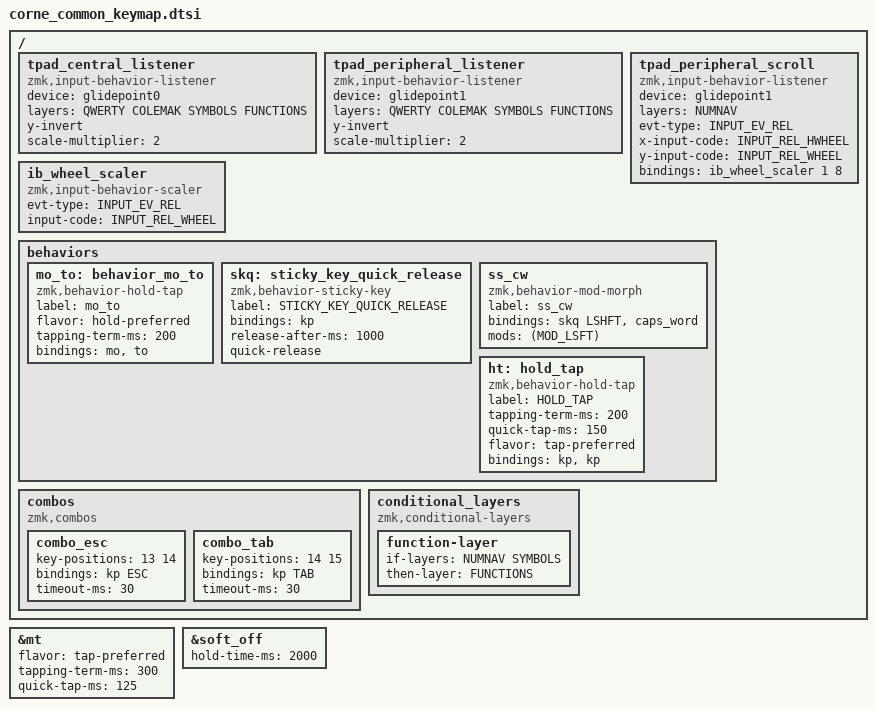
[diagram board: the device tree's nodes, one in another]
#include <behaviors.dtsi>
#include <dt-bindings/zmk/keys.h>
#include <dt-bindings/zmk/bt.h> 
#include <dt-bindings/zmk/rgb.h>
#include <dt-bindings/zmk/ext_power.h>
#include <dt-bindings/zmk/outputs.h>

#include <dt-bindings/zmk/mouse.h>
#include <behaviors/mouse_keys.dtsi>


#define QWERTY 0
#define COLEMAK 1
#define NUMNAV 2
#define SYMBOLS 3
#define FUNCTIONS 4

/ {
    /* assign `input-listener` to all pointing devices */
    /* &glidepoint0 on central, &glidepoint1 on peripheral */
    tpad_central_listener {
        compatible = "zmk,input-behavior-listener";
        device = <&glidepoint0>;
        layers = <QWERTY COLEMAK SYMBOLS FUNCTIONS>;
        y-invert;
        scale-multiplier = <2>;
    };

    tpad_peripheral_listener {
        compatible = "zmk,input-behavior-listener";
        device = <&glidepoint1>;
        layers = <QWERTY COLEMAK SYMBOLS FUNCTIONS>;
        y-invert;
        scale-multiplier = <2>;
    };

    tpad_peripheral_scroll {
        compatible = "zmk,input-behavior-listener";
        device = <&glidepoint1>;
        layers = <NUMNAV>;
        evt-type = <INPUT_EV_REL>;
        x-input-code = <INPUT_REL_HWHEEL>;
        y-input-code = <INPUT_REL_WHEEL>;
        bindings = <&ib_wheel_scaler 1 8>;
    };

    ib_wheel_scaler: ib_wheel_scaler {
        compatible = "zmk,input-behavior-scaler";
        #binding-cells = <2>;
        evt-type = <INPUT_EV_REL>;
        input-code = <INPUT_REL_WHEEL>;
    };
};

&mt {
  flavor = "tap-preferred";
  tapping-term-ms = <300>; 
  quick-tap-ms = <125>;
};

&soft_off {
    hold-time-ms = <2000>;
};

/ {
  behaviors {
    mo_to: behavior_mo_to {
         compatible = "zmk,behavior-hold-tap";
         label = "mo_to";
         #binding-cells = <2>;
         flavor = "hold-preferred";
         tapping-term-ms = <200>;
         bindings = <&mo>, <&to>;
    };

    skq: sticky_key_quick_release {
        compatible = "zmk,behavior-sticky-key";
        label = "STICKY_KEY_QUICK_RELEASE";
        #binding-cells = <1>;
        bindings = <&kp>;
        release-after-ms = <1000>;
        quick-release;
    };

    ss_cw: ss_cw {
         compatible = "zmk,behavior-mod-morph";
         #binding-cells = <0>;
         label = "ss_cw";
         bindings = <&skq LSHFT>, <&caps_word>;
         mods = <(MOD_LSFT)>;
    };

    ht: hold_tap {
        compatible = "zmk,behavior-hold-tap";
        label = "HOLD_TAP";
        #binding-cells = <2>;
        tapping-term-ms = <200>;
        quick-tap-ms = <150>;
        flavor = "tap-preferred";
        bindings = <&kp>, <&kp>;
    };
  };

  combos {
    compatible = "zmk,combos";

    combo_esc {
      key-positions = <13 14>;
      bindings = <&kp ESC>;
      timeout-ms = <30>;
    };

    combo_tab {
      key-positions = <14 15>;
      bindings = <&kp TAB>;
      timeout-ms = <30>;
    };
  };

  conditional_layers {
    compatible = "zmk,conditional-layers";
    function-layer {
      if-layers = <NUMNAV SYMBOLS>;
      then-layer = <FUNCTIONS>;
    };
  };
};

// QWERTY Layer (Corne 42 keys)
// -----------------------------------------------------------------------------------------
// | TAB  |  Q  |  W  |  E  |  R  |  T  |   |  Y  |  U   |  I  |  O  |  P  | BKSP |
// |CTRL  |  A  |  S  |  D  |  F  |  G  |   |  H  |  J   |  K  |  L  |  ;  |  '   |
// |SHFT  |  Z  |  X  |  C  |  V  |  B  |   |  N  |  M   |  ,  |  .  |  /  | ESC  |
//                    | WIN | NUM | SPC |   | ENT | SYM  | ALT  |

#define __________QWERTY_L1__________  &kp TAB    &kp Q  &kp W  &kp E        &kp R        &kp T
#define __________QWERTY_L2__________  &kp LCTRL  &kp A  &kp S  &kp D        &kp F        &kp G
#define __________QWERTY_L3__________  &kp LSHFT  &kp Z  &kp X  &kp C        &kp V        &kp B
#define _____QWERTY_TH_L_____  &kp LEFT_GUI &mo NUMNAV &kp SPACE

#define __________QWERTY_R1__________  &kp Y      &kp U      &kp I         &kp O        &kp P          &kp BACKSPACE
#define __________QWERTY_R2__________  &kp H      &kp J      &kp K         &kp L        &kp SEMICOLON  &kp SQT
#define __________QWERTY_R3__________  &kp N      &kp M      &kp COMMA     &kp PERIOD   &kp SLASH      &kp ESCAPE
#define _____QWERTY_TH_R_____  &kp ENTER &mo SYMBOLS &kp LEFT_ALT

// COLEMAK Layer
// -----------------------------------------------------------------------------------------
// | TAB  |  Q  |  W  |  F  |  P  |  G  |   |  J  |  L   |  U  |  Y  |  ;  | BKSP |
// |CTRL  |  A  |  R  |  S  |  T  |  D  |   |  H  |  N   |  E  |  I  |  O  |  '   |
// |SHFT  |  Z  |  X  |  C  |  V  |  B  |   |  K  |  M   |  ,  |  .  |  /  | ESC  |
//                    | WIN | NUM | SPC |   | ENT | SYM  | ALT  |

#define __________COLEMAK_L1__________  &kp TAB    &kp Q  &kp W  &kp F        &kp P        &kp G
#define __________COLEMAK_L2__________  &kp LCTRL  &kp A  &kp R  &kp S        &kp T        &kp D
#define __________COLEMAK_L3__________  &kp LSHFT  &kp Z  &kp X  &kp C        &kp V        &kp B
#define _____COLEMAK_TH_L_____  &kp LEFT_GUI &mo NUMNAV &kp SPACE

#define __________COLEMAK_R1__________  &kp J      &kp L      &kp U         &kp Y        &kp SEMICOLON  &kp BACKSPACE
#define __________COLEMAK_R2__________  &kp H      &kp N      &kp E         &kp I        &kp O          &kp SQT
#define __________COLEMAK_R3__________  &kp K      &kp M      &kp COMMA     &kp PERIOD   &kp SLASH      &kp ESCAPE
#define _____COLEMAK_TH_R_____  &kp ENTER &mo SYMBOLS &kp LEFT_ALT

// NUM-NAV Layer (combines number pad and navigation)
// -----------------------------------------------------------------------------------------
// | TAB  |  ---  |  7  |  8  |  9  |  ,  |   | --- | C+← |  UP | C+→ | PGUP |  BKSP |
// | CTRL | ---   |  4  |  5  |  6  |  0  |   | --- | LFT | DWN | RGT | INS  | DEL |
// | SHFT  | ---  |  1  |  2  |  3  |  .  |   | --- | HOM | C+X | END | PGDN | ---  |
//                      | --- | --- | SPC |   | RET | --- | --- |

#define __________NUMNAV_L1__________  &kp TAB     &trans  &kp N7        &kp N8        &kp N9        &kp COMMA
#define __________NUMNAV_L2__________  &kp LCTRL   &trans  &kp NUMBER_4  &kp N5        &kp NUMBER_6  &kp N0
#define __________NUMNAV_L3__________  &kp LSHFT   &trans  &kp NUMBER_1  &kp NUMBER_2  &kp NUMBER_3  &kp PERIOD
#define _____NUMNAV_TH_L_____  &trans &trans &kp SPACE

#define __________NUMNAV_R1__________  &trans  &kp LC(LEFT)    &kp UP    &kp LC(RIGHT)  &kp PAGE_UP    &kp BACKSPACE
#define __________NUMNAV_R2__________  &trans  &kp LEFT_ARROW  &kp DOWN  &kp RIGHT      &kp INS        &kp DELETE
#define __________NUMNAV_R3__________  &trans  &kp HOME        &kp LC(X) &kp END        &kp PAGE_DOWN  &trans
#define _____NUMNAV_TH_R_____  &kp RET &trans &trans

// SYMBOLS Layer
// -----------------------------------------------------------------------------------------
// | --- |  ~  |  $  |  [  |  ]  |  %  |   | --- |  "  |  <  |  >  |  `  | --- |
// | --- |  _  |  :  |  (  |  )  |  |  |   |  #  |  =  |  -  |  +  |  !  | --- |
// | --- | --- |  &  |  {  |  }  |  @  |   | --- |  /  |  *  |  \  |  ^  | --- |
//                   | --- | --- | --- |   | --- | --- | --- |

#define __________SYMBOLS_L1__________  &trans  &kp TILDE  &kp DOLLAR     &kp LEFT_BRACKET      &kp RIGHT_BRACKET      &kp PERCENT
#define __________SYMBOLS_L2__________  &trans  &kp UNDER  &kp COLON      &kp LEFT_PARENTHESIS  &kp RIGHT_PARENTHESIS  &kp PIPE
#define __________SYMBOLS_L3__________  &trans  &trans     &kp AMPERSAND  &kp LEFT_BRACE        &kp RIGHT_BRACE        &kp AT_SIGN
#define _____SYMBOLS_TH_L_____  &trans &trans &trans

#define __________SYMBOLS_R1__________  &trans  &kp DOUBLE_QUOTES  &kp LESS_THAN  &kp GREATER_THAN  &kp GRAVE        &trans
#define __________SYMBOLS_R2__________  &kp HASH &kp EQUAL         &kp MINUS      &kp PLUS          &kp EXCLAMATION  &trans
#define __________SYMBOLS_R3__________  &trans   &kp SLASH         &kp ASTERISK   &kp BACKSLASH     &kp CARET        &trans
#define _____SYMBOLS_TH_R_____  &trans &trans &trans

// FUNCTIONS Layer (activated when NUMNAV + SYMBOLS are both held)
// -----------------------------------------------------------------------------------------
// | --- | F12 | F7  | F8  | F9  |PREV |   |NEXT | QWERTY | COLEMAK | --- | --- | OFF|
// |CTRL | F11 | F4  | F5  | F6  | V- |   | V+ | BT0 | BT1 | BT2 | BT3 | --- |
// |SHFT | F10 | F1  | F2  | F3  |MUTE|   |PLAY| --- | --- | --- | --- | --- |
//                   | --- | --- | --- |   | --- | --- | --- |

#define __________FUNCTIONS_L1__________  &trans     &kp F12  &kp F7  &kp F8  &kp F9  &kp C_PREV
#define __________FUNCTIONS_L2__________  &kp LCTRL  &kp F11  &kp F4  &kp F5  &kp F6  &kp C_VOLUME_DOWN
#define __________FUNCTIONS_L3__________  &kp LSHFT  &kp F10  &kp F1  &kp F2  &kp F3  &kp C_MUTE
#define _____FUNCTIONS_TH_L_____  &trans &trans &trans

#define __________FUNCTIONS_R1__________  &kp C_NEXT        &to QWERTY        &to COLEMAK        &trans        &trans        &soft_off
#define __________FUNCTIONS_R2__________  &kp C_VOLUME_UP   &bt BT_SEL 0  &bt BT_SEL 1  &bt BT_SEL 2  &bt BT_SEL 3  &trans
#define __________FUNCTIONS_R3__________  &kp C_PLAY_PAUSE  &trans        &trans        &trans        &trans        &trans
#define _____FUNCTIONS_TH_R_____  &trans &trans &trans
